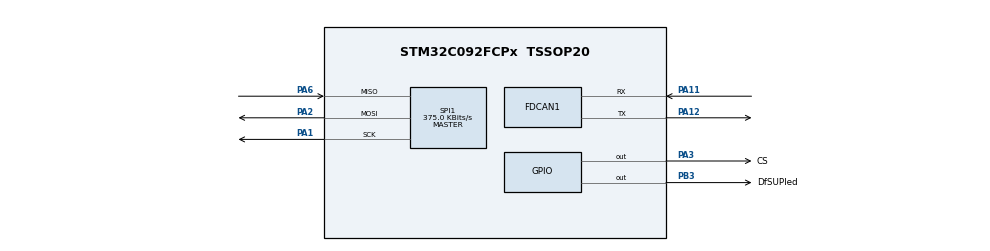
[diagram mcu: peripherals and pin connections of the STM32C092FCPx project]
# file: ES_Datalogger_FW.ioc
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FDCAN1.AutoRetransmission=ENABLE
FDCAN1.CalculateBaudRateNominal=250000
FDCAN1.CalculateTimeBitNominal=4000
FDCAN1.CalculateTimeQuantumNominal=250.0
FDCAN1.Mode=FDCAN_MODE_NORMAL
FDCAN1.NominalPrescaler=12
FDCAN1.NominalTimeSeg1=13
FDCAN1.NominalTimeSeg2=2
Mcu.Family=STM32C0
Mcu.Name=STM32C092FCPx
Mcu.Package=TSSOP20
NVIC.FDCAN1_IT0_IRQn=true\:0\:0\:false\:false\:true\:true\:true\:true
NVIC.FDCAN1_IT1_IRQn=true\:0\:0\:false\:false\:true\:true\:true\:true
PA1.Mode=Full_Duplex_Master
PA1.Signal=SPI1_SCK
PA11\ [PA9].Mode=FDCAN_Activate
PA11\ [PA9].Signal=FDCAN1_RX
PA12\ [PA10].Mode=FDCAN_Activate
PA12\ [PA10].Signal=FDCAN1_TX
PA13.Mode=Serial_Wire
PA13.Signal=DEBUG_SWDIO
PA14-BOOT0.Mode=Serial_Wire
PA14-BOOT0.Signal=DEBUG_SWCLK
PA14-BOOT0__PA15.StandardMode=true
PA2.Mode=Full_Duplex_Master
PA2.Signal=SPI1_MOSI
PA3.GPIO_Label=CS
PA3.PinState=GPIO_PIN_SET
PA3.Signal=GPIO_Output
PA6.Mode=Full_Duplex_Master
PA6.Signal=SPI1_MISO
PB0__PB1__PB2__PA8.StandardMode=true
PB3.GPIO_Label=DfSUPled
PB3.Signal=GPIO_Output
PB3__PB4__PB5__PB6.StandardMode=true
PB7__PB8.StandardMode=true
PC14-OSCX_IN(PC14).Mode=HSE-External-Oscillator
PC14-OSCX_IN(PC14).Signal=RCC_OSCX_IN
PC15-OSCX_OUT(PC15).Mode=HSE-External-Oscillator
PC15-OSCX_OUT(PC15).Signal=RCC_OSCX_OUT
ProjectManager.HeapSize=0x200
ProjectManager.StackSize=0x400
ProjectManager.TargetToolchain=STM32CubeIDE
RCC.ADCFreq_Value=48000000
RCC.AHBFreq_Value=48000000
RCC.CortexFreq_Value=48000000
RCC.EXTERNAL_CLOCK_VALUE=12288000
RCC.HCLKFreq_Value=48000000
RCC.HSE_VALUE=8000000
RCC.HSIKERCLKDivider=RCC_HSIKER_DIV1
RCC.HSISYSCLKDivider=RCC_HSI_DIV1
RCC.HSI_VALUE=48000000
RCC.LSE_VALUE=32768
RCC.SYSCLKFreq_VALUE=48000000
SPI1.BaudRatePrescaler=SPI_BAUDRATEPRESCALER_128
SPI1.CalculateBaudRate=375.0 KBits/s
SPI1.DataSize=SPI_DATASIZE_8BIT
SPI1.Direction=SPI_DIRECTION_2LINES
SPI1.Mode=SPI_MODE_MASTER
SPI1.NSSPMode=SPI_NSS_PULSE_DISABLE
SPI1.VirtualType=VM_MASTER
board=custom

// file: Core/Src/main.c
/* USER CODE BEGIN Header */
/**
  ******************************************************************************
  * @file           : main.c
  * @brief          : Main program body
  ******************************************************************************
  * @attention
  *
  * Copyright (c) 2026 STMicroelectronics.
  * All rights reserved.
  *
  * This software is licensed under terms that can be found in the LICENSE file
  * in the root directory of this software component.
  * If no LICENSE file comes with this software, it is provided AS-IS.
  *
  ******************************************************************************
  */
/* USER CODE END Header */
#include "main.h"

/* USER CODE BEGIN Includes */
#include "can.h"
#include "microsd.h"
/* USER CODE END Includes */

FDCAN_HandleTypeDef hfdcan1;

SPI_HandleTypeDef hspi1;

/* USER CODE BEGIN PV */
volatile DICCP_t DICCP = {0};
uint32_t last_sd_log_tick = 0;
const uint32_t SD_LOG_PERIOD_MS = 200;
/* USER CODE END PV */

void SystemClock_Config(void);
static void MX_GPIO_Init(void);
static void MX_FDCAN1_Init(void);
static void MX_SPI1_Init(void);

int main(void)
{

  /* MCU Configuration--------------------------------------------------------*/

  /* Reset of all peripherals, Initializes the Flash interface and the Systick. */
  HAL_Init();

  /* Configure the system clock */
  SystemClock_Config();

  /* Initialize all configured peripherals */
  MX_GPIO_Init();
  MX_FDCAN1_Init();
  MX_SPI1_Init();
  /* USER CODE BEGIN 2 */

  CAN_Init_Custom(&hfdcan1);
  MicroSD_Init(); /* Corregit: Inicialitza la SD un cop SPI1 i HAL estan actius */

  /* USER CODE END 2 */

  /* Infinite loop */
  while (1)
  {

    /* USER CODE BEGIN 3 */
	  uint32_t current_tick = HAL_GetTick();

	  // Guarda l'estat actual de la llista DICCP a la MicroSD cada 500 ms
	  if ((current_tick - last_sd_log_tick) >= SD_LOG_PERIOD_MS) {
		  last_sd_log_tick = current_tick;
		  MicroSD_LogData(&DICCP);
	  }
  }
  /* USER CODE END 3 */
}

void SystemClock_Config(void)
{
  RCC_OscInitTypeDef RCC_OscInitStruct = {0};
  RCC_ClkInitTypeDef RCC_ClkInitStruct = {0};

  __HAL_FLASH_SET_LATENCY(FLASH_LATENCY_1);

  /** Initializes the RCC Oscillators according to the specified parameters
  * in the RCC_OscInitTypeDef structure.
  */
  RCC_OscInitStruct.OscillatorType = RCC_OSCILLATORTYPE_HSI;
  RCC_OscInitStruct.HSIState = RCC_HSI_ON;
  RCC_OscInitStruct.HSIDiv = RCC_HSI_DIV1;
  RCC_OscInitStruct.HSICalibrationValue = RCC_HSICALIBRATION_DEFAULT;
  if (HAL_RCC_OscConfig(&RCC_OscInitStruct) != HAL_OK)
  {
    Error_Handler();
  }

  /** Initializes the CPU, AHB and APB buses clocks
  */
  RCC_ClkInitStruct.ClockType = RCC_CLOCKTYPE_HCLK|RCC_CLOCKTYPE_SYSCLK
                              |RCC_CLOCKTYPE_PCLK1;
  RCC_ClkInitStruct.SYSCLKSource = RCC_SYSCLKSOURCE_HSI;
  RCC_ClkInitStruct.SYSCLKDivider = RCC_SYSCLK_DIV1;
  RCC_ClkInitStruct.AHBCLKDivider = RCC_HCLK_DIV1;
  RCC_ClkInitStruct.APB1CLKDivider = RCC_APB1_DIV1;

  if (HAL_RCC_ClockConfig(&RCC_ClkInitStruct, FLASH_LATENCY_1) != HAL_OK)
  {
    Error_Handler();
  }
}

static void MX_FDCAN1_Init(void)
{

  hfdcan1.Instance = FDCAN1;
  hfdcan1.Init.ClockDivider = FDCAN_CLOCK_DIV1;
  hfdcan1.Init.FrameFormat = FDCAN_FRAME_CLASSIC;
  hfdcan1.Init.Mode = FDCAN_MODE_NORMAL;
  hfdcan1.Init.AutoRetransmission = ENABLE;
  hfdcan1.Init.TransmitPause = DISABLE;
  hfdcan1.Init.ProtocolException = DISABLE;
  hfdcan1.Init.NominalPrescaler = 12;
  hfdcan1.Init.NominalSyncJumpWidth = 1;
  hfdcan1.Init.NominalTimeSeg1 = 13;
  hfdcan1.Init.NominalTimeSeg2 = 2;
  hfdcan1.Init.DataPrescaler = 1;
  hfdcan1.Init.DataSyncJumpWidth = 1;
  hfdcan1.Init.DataTimeSeg1 = 1;
  hfdcan1.Init.DataTimeSeg2 = 1;
  hfdcan1.Init.StdFiltersNbr = 0;
  hfdcan1.Init.ExtFiltersNbr = 0;
  hfdcan1.Init.TxFifoQueueMode = FDCAN_TX_FIFO_OPERATION;
  if (HAL_FDCAN_Init(&hfdcan1) != HAL_OK)
  {
    Error_Handler();
  }

}

static void MX_SPI1_Init(void)
{

  /* SPI1 parameter configuration*/
  hspi1.Instance = SPI1;
  hspi1.Init.Mode = SPI_MODE_MASTER;
  hspi1.Init.Direction = SPI_DIRECTION_2LINES;
  hspi1.Init.DataSize = SPI_DATASIZE_8BIT;
  hspi1.Init.CLKPolarity = SPI_POLARITY_LOW;
  hspi1.Init.CLKPhase = SPI_PHASE_1EDGE;
  hspi1.Init.NSS = SPI_NSS_SOFT;
  hspi1.Init.BaudRatePrescaler = SPI_BAUDRATEPRESCALER_128;
  hspi1.Init.FirstBit = SPI_FIRSTBIT_MSB;
  hspi1.Init.TIMode = SPI_TIMODE_DISABLE;
  hspi1.Init.CRCCalculation = SPI_CRCCALCULATION_DISABLE;
  hspi1.Init.CRCPolynomial = 7;
  hspi1.Init.CRCLength = SPI_CRC_LENGTH_DATASIZE;
  hspi1.Init.NSSPMode = SPI_NSS_PULSE_DISABLE;
  if (HAL_SPI_Init(&hspi1) != HAL_OK)
  {
    Error_Handler();
  }

}

static void MX_GPIO_Init(void)
{
  GPIO_InitTypeDef GPIO_InitStruct = {0};

  /* GPIO Ports Clock Enable */
  __HAL_RCC_GPIOC_CLK_ENABLE();
  __HAL_RCC_GPIOA_CLK_ENABLE();
  __HAL_RCC_GPIOB_CLK_ENABLE();

  /*Configure GPIO pin Output Level */
  HAL_GPIO_WritePin(CS_GPIO_Port, CS_Pin, GPIO_PIN_SET);

  /*Configure GPIO pin Output Level */
  HAL_GPIO_WritePin(DfSUPled_GPIO_Port, DfSUPled_Pin, GPIO_PIN_RESET);

  /*Configure GPIO pin : CS_Pin */
  GPIO_InitStruct.Pin = CS_Pin;
  GPIO_InitStruct.Mode = GPIO_MODE_OUTPUT_PP;
  GPIO_InitStruct.Pull = GPIO_NOPULL;
  GPIO_InitStruct.Speed = GPIO_SPEED_FREQ_LOW;
  HAL_GPIO_Init(CS_GPIO_Port, &GPIO_InitStruct);

  /*Configure GPIO pin : DfSUPled_Pin */
  GPIO_InitStruct.Pin = DfSUPled_Pin;
  GPIO_InitStruct.Mode = GPIO_MODE_OUTPUT_PP;
  GPIO_InitStruct.Pull = GPIO_NOPULL;
  GPIO_InitStruct.Speed = GPIO_SPEED_FREQ_LOW;
  HAL_GPIO_Init(DfSUPled_GPIO_Port, &GPIO_InitStruct);

}

void Error_Handler(void)
{
  __disable_irq();
  while (1)
  {
  }
}
